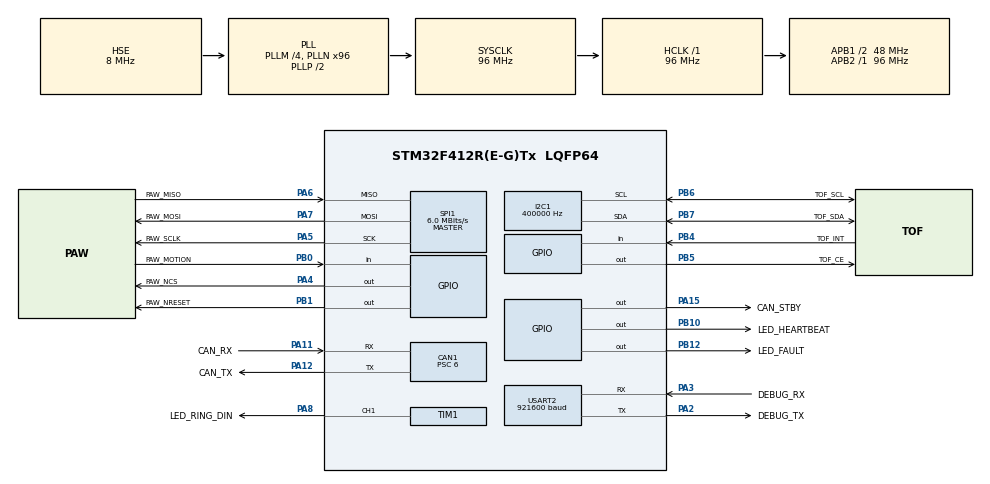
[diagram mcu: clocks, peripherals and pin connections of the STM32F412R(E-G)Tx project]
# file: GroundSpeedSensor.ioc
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CAN1.ABOM=ENABLE
CAN1.BS1=CAN_BS1_13TQ
CAN1.BS2=CAN_BS2_2TQ
CAN1.CalculateBaudRate=500000
CAN1.CalculateTimeBit=2000
CAN1.CalculateTimeQuantum=125.0
CAN1.NART=ENABLE
CAN1.Prescaler=6
CAN1.SJW=CAN_SJW_2TQ
CAN1.TXFP=ENABLE
Dma.Request0=TIM1_CH1
Dma.Request1=USART2_TX
Dma.TIM1_CH1.0.Direction=DMA_MEMORY_TO_PERIPH
Dma.TIM1_CH1.0.FIFOMode=DMA_FIFOMODE_DISABLE
Dma.TIM1_CH1.0.Instance=DMA2_Stream1
Dma.TIM1_CH1.0.MemDataAlignment=DMA_MDATAALIGN_HALFWORD
Dma.TIM1_CH1.0.MemInc=DMA_MINC_ENABLE
Dma.TIM1_CH1.0.Mode=DMA_NORMAL
Dma.TIM1_CH1.0.PeriphDataAlignment=DMA_PDATAALIGN_HALFWORD
Dma.TIM1_CH1.0.PeriphInc=DMA_PINC_DISABLE
Dma.TIM1_CH1.0.Priority=DMA_PRIORITY_HIGH
Dma.USART2_TX.1.Direction=DMA_MEMORY_TO_PERIPH
Dma.USART2_TX.1.FIFOMode=DMA_FIFOMODE_DISABLE
Dma.USART2_TX.1.Instance=DMA1_Stream6
Dma.USART2_TX.1.MemDataAlignment=DMA_MDATAALIGN_BYTE
Dma.USART2_TX.1.MemInc=DMA_MINC_ENABLE
Dma.USART2_TX.1.Mode=DMA_NORMAL
Dma.USART2_TX.1.PeriphDataAlignment=DMA_PDATAALIGN_BYTE
Dma.USART2_TX.1.PeriphInc=DMA_PINC_DISABLE
Dma.USART2_TX.1.Priority=DMA_PRIORITY_LOW
I2C1.ClockSpeed=400000
I2C1.I2C_Mode=I2C_Fast
IWDG.Prescaler=IWDG_PRESCALER_32
IWDG.Reload=500
Mcu.Family=STM32F4
Mcu.Name=STM32F412R(E-G)Tx
Mcu.Package=LQFP64
NVIC.CAN1_RX0_IRQn=true\:3\:0\:false\:false\:true\:true\:true\:true
NVIC.DMA1_Stream6_IRQn=true\:5\:0\:false\:false\:true\:false\:true\:true
NVIC.DMA2_Stream1_IRQn=true\:2\:0\:false\:false\:true\:false\:true\:true
NVIC.PriorityGroup=NVIC_PRIORITYGROUP_4
NVIC.USART2_IRQn=true\:5\:0\:false\:false\:true\:true\:true\:true
PA11.GPIO_Label=CAN_RX
PA11.GPIO_PuPd=GPIO_PULLUP
PA11.Mode=CAN_Activate
PA11.Signal=CAN1_RX
PA12.GPIO_Label=CAN_TX
PA12.Mode=CAN_Activate
PA12.Signal=CAN1_TX
PA13.Mode=Serial_Wire
PA13.Signal=SYS_JTMS-SWDIO
PA14.Mode=Serial_Wire
PA14.Signal=SYS_JTCK-SWCLK
PA15.GPIO_Label=CAN_STBY
PA15.PinState=GPIO_PIN_RESET
PA15.Signal=GPIO_Output
PA2.GPIO_Label=DEBUG_TX
PA2.Mode=Asynchronous
PA2.Signal=USART2_TX
PA3.GPIO_Label=DEBUG_RX
PA3.Mode=Asynchronous
PA3.Signal=USART2_RX
PA4.GPIO_Label=PAW_NCS
PA4.GPIO_Speed=GPIO_SPEED_FREQ_VERY_HIGH
PA4.PinState=GPIO_PIN_SET
PA4.Signal=GPIO_Output
PA5.GPIO_Label=PAW_SCLK
PA5.Mode=Full_Duplex_Master
PA5.Signal=SPI1_SCK
PA6.GPIO_Label=PAW_MISO
PA6.Mode=Full_Duplex_Master
PA6.Signal=SPI1_MISO
PA7.GPIO_Label=PAW_MOSI
PA7.Mode=Full_Duplex_Master
PA7.Signal=SPI1_MOSI
PA8.GPIO_Label=LED_RING_DIN
PA8.GPIO_Speed=GPIO_SPEED_FREQ_HIGH
PA8.Signal=S_TIM1_CH1
PB0.GPIO_Label=PAW_MOTION
PB0.GPIO_PuPd=GPIO_PULLUP
PB0.Signal=GPIO_Input
PB1.GPIO_Label=PAW_NRESET
PB1.PinState=GPIO_PIN_SET
PB1.Signal=GPIO_Output
PB10.GPIO_Label=LED_HEARTBEAT
PB10.Signal=GPIO_Output
PB12.GPIO_Label=LED_FAULT
PB12.Signal=GPIO_Output
PB4.GPIO_Label=TOF_INT
PB4.GPIO_PuPd=GPIO_PULLUP
PB4.Signal=GPIO_Input
PB5.GPIO_Label=TOF_CE
PB5.PinState=GPIO_PIN_SET
PB5.Signal=GPIO_Output
PB6.GPIO_Label=TOF_SCL
PB6.Mode=I2C
PB6.Signal=I2C1_SCL
PB7.GPIO_Label=TOF_SDA
PB7.Mode=I2C
PB7.Signal=I2C1_SDA
PH0\ -\ OSC_IN.Mode=HSE-External-Oscillator
PH0\ -\ OSC_IN.Signal=RCC_OSC_IN
PH1\ -\ OSC_OUT.Mode=HSE-External-Oscillator
PH1\ -\ OSC_OUT.Signal=RCC_OSC_OUT
ProjectManager.HeapSize=0x200
ProjectManager.StackSize=0x400
ProjectManager.TargetToolchain=STM32CubeIDE
RCC.AHBFreq_Value=96000000
RCC.APB1CLKDivider=RCC_HCLK_DIV2
RCC.APB1Freq_Value=48000000
RCC.APB1TimFreq_Value=96000000
RCC.APB2Freq_Value=96000000
RCC.APB2TimFreq_Value=96000000
RCC.CortexFreq_Value=96000000
RCC.HCLKFreq_Value=96000000
RCC.HSE_VALUE=8000000
RCC.PLLM=4
RCC.PLLN=96
RCC.PLLQ=4
RCC.PLLSourceVirtual=RCC_PLLSOURCE_HSE
RCC.SYSCLKFreq_VALUE=96000000
RCC.SYSCLKSource=RCC_SYSCLKSOURCE_PLLCLK
RCC.USBFreq_Value=48000000
RCC.VCOOutputFreq_Value=192000000
SH.S_TIM1_CH1.0=TIM1_CH1,PWM Generation1 CH1
SPI1.BaudRatePrescaler=SPI_BAUDRATEPRESCALER_16
SPI1.CLKPhase=SPI_PHASE_2EDGE
SPI1.CLKPolarity=SPI_POLARITY_HIGH
SPI1.CalculateBaudRate=6.0 MBits/s
SPI1.Direction=SPI_DIRECTION_2LINES
SPI1.Mode=SPI_MODE_MASTER
SPI1.VirtualType=VM_MASTER
TIM1.AutoReloadPreload=TIM_AUTORELOAD_PRELOAD_ENABLE
TIM1.Channel-PWM\ Generation1\ CH1=TIM_CHANNEL_1
TIM1.Period=120-1
TIM1.Prescaler=0
TIM2.Period=0xFFFFFFFF
TIM2.Prescaler=96-1
USART2.BaudRate=921600
USART2.VirtualMode=VM_ASYNC
VP_IWDG_VS_IWDG.Mode=IWDG_Activate
VP_TIM1_VS_ClockSourceINT.Mode=Internal
VP_TIM2_VS_ClockSourceINT.Mode=Internal
board=custom

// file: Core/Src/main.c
/* USER CODE BEGIN Header */
/**
  ******************************************************************************
  * @file           : main.c
  * @brief          : Main program body
  ******************************************************************************
  * @attention
  *
  * Copyright (c) 2026 STMicroelectronics.
  * All rights reserved.
  *
  * This software is licensed under terms that can be found in the LICENSE file
  * in the root directory of this software component.
  * If no LICENSE file comes with this software, it is provided AS-IS.
  *
  ******************************************************************************
  */
/* USER CODE END Header */
#include "main.h"
#include "can.h"
#include "dma.h"
#include "i2c.h"
#include "iwdg.h"
#include "spi.h"
#include "tim.h"
#include "usart.h"
#include "gpio.h"

/* USER CODE BEGIN Includes */
#include "brain.h"
/* USER CODE END Includes */

void SystemClock_Config(void);

int main(void)
{

  /* MCU Configuration--------------------------------------------------------*/

  /* Reset of all peripherals, Initializes the Flash interface and the Systick. */
  HAL_Init();

  /* Configure the system clock */
  SystemClock_Config();

  /* Initialize all configured peripherals */
  MX_GPIO_Init();
  MX_DMA_Init();
  MX_CAN1_Init();
  MX_SPI1_Init();
  MX_I2C1_Init();
  MX_TIM1_Init();
  MX_TIM2_Init();
  MX_USART2_UART_Init();
  MX_IWDG_Init();
  /* USER CODE BEGIN 2 */
  brain_start();
  /* USER CODE END 2 */

  /* Infinite loop */
  while (1)
  {

    /* USER CODE BEGIN 3 */
    brain_loop();
  }
  /* USER CODE END 3 */
}

void SystemClock_Config(void)
{
  RCC_OscInitTypeDef RCC_OscInitStruct = {0};
  RCC_ClkInitTypeDef RCC_ClkInitStruct = {0};

  /** Configure the main internal regulator output voltage
  */
  __HAL_RCC_PWR_CLK_ENABLE();
  __HAL_PWR_VOLTAGESCALING_CONFIG(PWR_REGULATOR_VOLTAGE_SCALE1);

  /** Initializes the RCC Oscillators according to the specified parameters
  * in the RCC_OscInitTypeDef structure.
  */
  RCC_OscInitStruct.OscillatorType = RCC_OSCILLATORTYPE_LSI|RCC_OSCILLATORTYPE_HSE;
  RCC_OscInitStruct.HSEState = RCC_HSE_ON;
  RCC_OscInitStruct.LSIState = RCC_LSI_ON;
  RCC_OscInitStruct.PLL.PLLState = RCC_PLL_ON;
  RCC_OscInitStruct.PLL.PLLSource = RCC_PLLSOURCE_HSE;
  RCC_OscInitStruct.PLL.PLLM = 4;
  RCC_OscInitStruct.PLL.PLLN = 96;
  RCC_OscInitStruct.PLL.PLLP = RCC_PLLP_DIV2;
  RCC_OscInitStruct.PLL.PLLQ = 4;
  RCC_OscInitStruct.PLL.PLLR = 2;
  if (HAL_RCC_OscConfig(&RCC_OscInitStruct) != HAL_OK)
  {
    Error_Handler();
  }

  /** Initializes the CPU, AHB and APB buses clocks
  */
  RCC_ClkInitStruct.ClockType = RCC_CLOCKTYPE_HCLK|RCC_CLOCKTYPE_SYSCLK
                              |RCC_CLOCKTYPE_PCLK1|RCC_CLOCKTYPE_PCLK2;
  RCC_ClkInitStruct.SYSCLKSource = RCC_SYSCLKSOURCE_PLLCLK;
  RCC_ClkInitStruct.AHBCLKDivider = RCC_SYSCLK_DIV1;
  RCC_ClkInitStruct.APB1CLKDivider = RCC_HCLK_DIV2;
  RCC_ClkInitStruct.APB2CLKDivider = RCC_HCLK_DIV1;

  if (HAL_RCC_ClockConfig(&RCC_ClkInitStruct, FLASH_LATENCY_3) != HAL_OK)
  {
    Error_Handler();
  }
}

void Error_Handler(void)
{
  __disable_irq();
  while (1)
  {
  }
}
